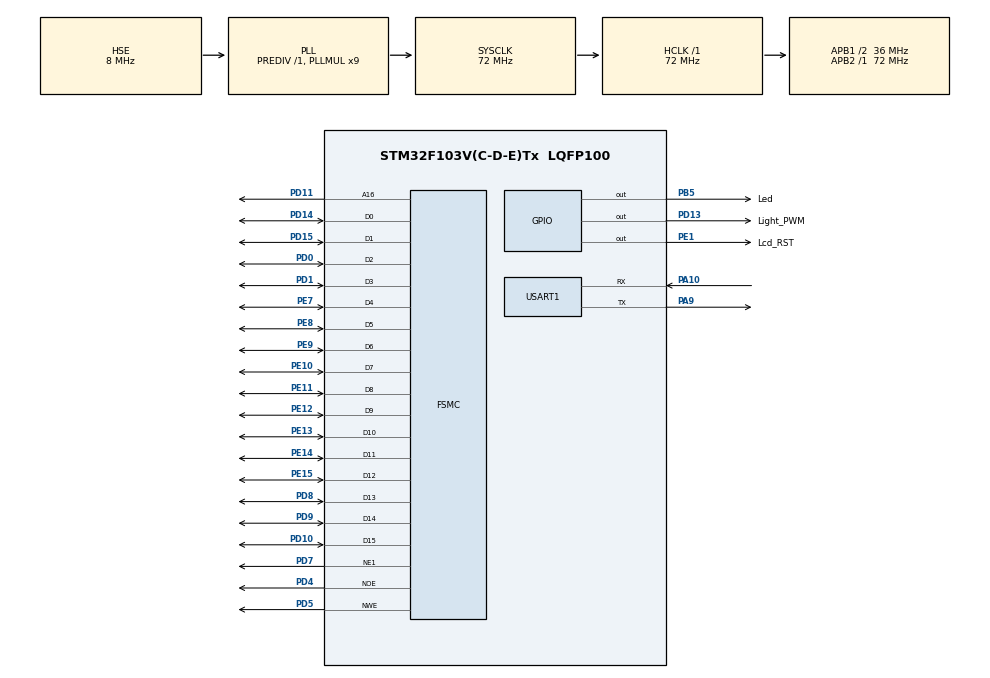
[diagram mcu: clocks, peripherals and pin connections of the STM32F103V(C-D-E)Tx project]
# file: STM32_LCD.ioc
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Mcu.Family=STM32F1
Mcu.Name=STM32F103V(C-D-E)Tx
Mcu.Package=LQFP100
NVIC.PriorityGroup=NVIC_PRIORITYGROUP_4
NVIC.TIM1_UP_IRQn=true\:0\:0\:false\:false\:true\:false
NVIC.TimeBase=TIM1_UP_IRQn
NVIC.TimeBaseIP=TIM1
OSC_IN.Mode=HSE-External-Oscillator
OSC_IN.Signal=RCC_OSC_IN
OSC_OUT.Mode=HSE-External-Oscillator
OSC_OUT.Signal=RCC_OSC_OUT
PA10.Mode=Asynchronous
PA10.Signal=USART1_RX
PA9.Mode=Asynchronous
PA9.Signal=USART1_TX
PB5.GPIO_Label=Led
PB5.Signal=GPIO_Output
PC14-OSC32_IN.Mode=LSE-External-Oscillator
PC14-OSC32_IN.Signal=RCC_OSC32_IN
PC15-OSC32_OUT.Mode=LSE-External-Oscillator
PC15-OSC32_OUT.Signal=RCC_OSC32_OUT
PD0.Mode=16b-d1
PD0.Signal=FSMC_D2
PD1.Mode=16b-d1
PD1.Signal=FSMC_D3
PD10.Mode=16b-d1
PD10.Signal=FSMC_D15
PD11.Mode=A16_1
PD11.Signal=FSMC_A16
PD13.GPIO_Label=Light_PWM
PD13.GPIO_Speed=GPIO_SPEED_FREQ_HIGH
PD13.Signal=GPIO_Output
PD14.Mode=16b-d1
PD14.Signal=FSMC_D0
PD15.Mode=16b-d1
PD15.Signal=FSMC_D1
PD4.Mode=Lcd1
PD4.Signal=FSMC_NOE
PD5.Mode=Lcd1
PD5.Signal=FSMC_NWE
PD7.Mode=NorPsramChipSelect1_1
PD7.Signal=FSMC_NE1
PD8.Mode=16b-d1
PD8.Signal=FSMC_D13
PD9.Mode=16b-d1
PD9.Signal=FSMC_D14
PE1.GPIO_Label=Lcd_RST
PE1.Signal=GPIO_Output
PE10.Mode=16b-d1
PE10.Signal=FSMC_D7
PE11.Mode=16b-d1
PE11.Signal=FSMC_D8
PE12.Mode=16b-d1
PE12.Signal=FSMC_D9
PE13.Mode=16b-d1
PE13.Signal=FSMC_D10
PE14.Mode=16b-d1
PE14.Signal=FSMC_D11
PE15.Mode=16b-d1
PE15.Signal=FSMC_D12
PE7.Mode=16b-d1
PE7.Signal=FSMC_D4
PE8.Mode=16b-d1
PE8.Signal=FSMC_D5
PE9.Mode=16b-d1
PE9.Signal=FSMC_D6
ProjectManager.HeapSize=0x200
ProjectManager.StackSize=0x400
ProjectManager.TargetToolchain=Makefile
RCC.AHBFreq_Value=72000000
RCC.APB1CLKDivider=RCC_HCLK_DIV2
RCC.APB1Freq_Value=36000000
RCC.APB1TimFreq_Value=72000000
RCC.APB2Freq_Value=72000000
RCC.APB2TimFreq_Value=72000000
RCC.HCLKFreq_Value=72000000
RCC.PLLMUL=RCC_PLL_MUL9
RCC.PLLSourceVirtual=RCC_PLLSOURCE_HSE
RCC.SYSCLKFreq_VALUE=72000000
RCC.SYSCLKSource=RCC_SYSCLKSOURCE_PLLCLK
RCC.USBFreq_Value=72000000
USART1.VirtualMode=VM_ASYNC
VP_SYS_VS_ND.Mode=No_Debug
VP_SYS_VS_tim1.Mode=TIM1
board=custom

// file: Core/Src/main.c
/* USER CODE BEGIN Header */
/**
  ******************************************************************************
  * @file           : main.c
  * @brief          : Main program body
  ******************************************************************************
  ** This notice applies to any and all portions of this file
  * that are not between comment pairs USER CODE BEGIN and
  * USER CODE END. Other portions of this file, whether
  * inserted by the user or by software development tools
  * are owned by their respective copyright owners.
  *
  * COPYRIGHT(c) 2018 STMicroelectronics
  *
  * Redistribution and use in source and binary forms, with or without modification,
  * are permitted provided that the following conditions are met:
  *   1. Redistributions of source code must retain the above copyright notice,
  *      this list of conditions and the following disclaimer.
  *   2. Redistributions in binary form must reproduce the above copyright notice,
  *      this list of conditions and the following disclaimer in the documentation
  *      and/or other materials provided with the distribution.
  *   3. Neither the name of STMicroelectronics nor the names of its contributors
  *      may be used to endorse or promote products derived from this software
  *      without specific prior written permission.
  *
  * THIS SOFTWARE IS PROVIDED BY THE COPYRIGHT HOLDERS AND CONTRIBUTORS "AS IS"
  * AND ANY EXPRESS OR IMPLIED WARRANTIES, INCLUDING, BUT NOT LIMITED TO, THE
  * IMPLIED WARRANTIES OF MERCHANTABILITY AND FITNESS FOR A PARTICULAR PURPOSE ARE
  * DISCLAIMED. IN NO EVENT SHALL THE COPYRIGHT HOLDER OR CONTRIBUTORS BE LIABLE
  * FOR ANY DIRECT, INDIRECT, INCIDENTAL, SPECIAL, EXEMPLARY, OR CONSEQUENTIAL
  * DAMAGES (INCLUDING, BUT NOT LIMITED TO, PROCUREMENT OF SUBSTITUTE GOODS OR
  * SERVICES; LOSS OF USE, DATA, OR PROFITS; OR BUSINESS INTERRUPTION) HOWEVER
  * CAUSED AND ON ANY THEORY OF LIABILITY, WHETHER IN CONTRACT, STRICT LIABILITY,
  * OR TORT (INCLUDING NEGLIGENCE OR OTHERWISE) ARISING IN ANY WAY OUT OF THE USE
  * OF THIS SOFTWARE, EVEN IF ADVISED OF THE POSSIBILITY OF SUCH DAMAGE.
  *
  ******************************************************************************
  */
/* USER CODE END Header */

#include "main.h"
#include "usart.h"
#include "gpio.h"
#include "fsmc.h"

/* USER CODE BEGIN Includes */
#include <stdio.h>
#include "lcd.h"
/* USER CODE END Includes */

/* USER CODE BEGIN PV */
static uint16_t cnt = 0;
/* USER CODE END PV */

void SystemClock_Config(void);

int main(void)
{

  /* MCU Configuration--------------------------------------------------------*/

  /* Reset of all peripherals, Initializes the Flash interface and the Systick. */
  HAL_Init();

  /* Configure the system clock */
  SystemClock_Config();

  /* Initialize all configured peripherals */
  MX_GPIO_Init();
  MX_FSMC_Init();
  MX_USART1_UART_Init();
  /* USER CODE BEGIN 2 */
  LCD_Init();
  /* USER CODE END 2 */

  /* Infinite loop */
  while (1)
  {

    /* USER CODE BEGIN 3 */
    HAL_Delay(1000);
    tftprintf("I am counting 2 %d", cnt++);
  }
  /* USER CODE END 3 */
}

void SystemClock_Config(void)
{
  RCC_OscInitTypeDef RCC_OscInitStruct = {0};
  RCC_ClkInitTypeDef RCC_ClkInitStruct = {0};

  /**Initializes the CPU, AHB and APB busses clocks
  */
  RCC_OscInitStruct.OscillatorType = RCC_OSCILLATORTYPE_HSE;
  RCC_OscInitStruct.HSEState = RCC_HSE_ON;
  RCC_OscInitStruct.HSEPredivValue = RCC_HSE_PREDIV_DIV1;
  RCC_OscInitStruct.HSIState = RCC_HSI_ON;
  RCC_OscInitStruct.PLL.PLLState = RCC_PLL_ON;
  RCC_OscInitStruct.PLL.PLLSource = RCC_PLLSOURCE_HSE;
  RCC_OscInitStruct.PLL.PLLMUL = RCC_PLL_MUL9;
  if (HAL_RCC_OscConfig(&RCC_OscInitStruct) != HAL_OK)
  {
    Error_Handler();
  }
  /**Initializes the CPU, AHB and APB busses clocks
  */
  RCC_ClkInitStruct.ClockType = RCC_CLOCKTYPE_HCLK|RCC_CLOCKTYPE_SYSCLK
                              |RCC_CLOCKTYPE_PCLK1|RCC_CLOCKTYPE_PCLK2;
  RCC_ClkInitStruct.SYSCLKSource = RCC_SYSCLKSOURCE_PLLCLK;
  RCC_ClkInitStruct.AHBCLKDivider = RCC_SYSCLK_DIV1;
  RCC_ClkInitStruct.APB1CLKDivider = RCC_HCLK_DIV2;
  RCC_ClkInitStruct.APB2CLKDivider = RCC_HCLK_DIV1;

  if (HAL_RCC_ClockConfig(&RCC_ClkInitStruct, FLASH_LATENCY_2) != HAL_OK)
  {
    Error_Handler();
  }
}

void HAL_TIM_PeriodElapsedCallback(TIM_HandleTypeDef *htim)
{
  if (htim->Instance == TIM1) {
    HAL_IncTick();
  }
}

void Error_Handler(void)
{
}

/************************ (C) COPYRIGHT STMicroelectronics *****END OF FILE****/
